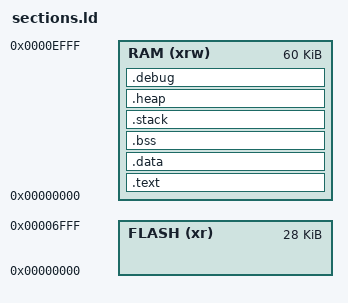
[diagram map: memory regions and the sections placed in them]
_STACK_SIZE = 2K;
_HEAP_SIZE = 2K;

MEMORY
{
    /* FLASH and RAM must have the same memory origin */
    FLASH(xr)       : ORIGIN = 0x00000000, LENGTH = 0x007000
    RAM  (xrw)       : ORIGIN = 0x00000000, LENGTH = 0x00F000
}

SECTIONS {
    /* The program code and other data goes into FLASH */
    .text :
    {
        . = ALIGN(4);
        *(.text)           /* .text sections (code) */
        *(.text*)          /* .text* sections (code) */
        *(.rodata)         /* .rodata sections (constants, strings, etc.) */
        *(.rodata*)        /* .rodata* sections (constants, strings, etc.) */
        *(.srodata)        /* .rodata sections (constants, strings, etc.) */
        *(.srodata*)       /* .rodata* sections (constants, strings, etc.) */
        . = ALIGN(4);
        _etext = .;        /* define a global symbol at end of code */
        _sidata = _etext;  /* This is used by the startup in order to initialize the .data secion */
        . = ALIGN(4);
    } >RAM


    /* This is the initialized data section
    The program executes knowing that the data is in the RAM
    but the loader puts the initial values in the FLASH (inidata).
    It is one task of the startup to copy the initial values from FLASH to RAM. */
    .data : AT ( _sidata )
    {
        . = ALIGN(4);
        _sdata = .;        /* create a global symbol at data start; used by startup code in order to initialise the .data section in RAM */
        . = ALIGN(4);
        /* We add small data before data, and align to 4, that seems to be the right way */
        *(.sdata)           /* .sdata sections */
        *(.sdata*)          /* .sdata* sections */
        . = ALIGN(4);
        *(.data)           /* .data sections */
        *(.data*)          /* .data* sections */
        . = ALIGN(4);
        _edata = .;        /* define a global symbol at data end; used by startup code in order to initialise the .data section in RAM */
    } >RAM

    /* Uninitialized data section */
    .bss :
    {
        . = ALIGN(4);
        _sbss = .;         /* define a global symbol at bss start; used by startup code */
        *(.bss)
        *(.bss*)
        *(.sbss)
        *(.sbss*)
        *(COMMON)

        . = ALIGN(4);
        _ebss = .;         /* define a global symbol at bss end; used by startup code */
    } >RAM

    /* Generate Stack and Heap definitions
    * Stack grows downwards
    */
   .stack : {
       _stack_end = .;
       . += _STACK_SIZE;
       . = ALIGN(4);
       _stack = .;
       __stack = _stack;
       . = ALIGN(4); 
    } > RAM

    /* Heap grows upwards */
    .heap : {
       . = ALIGN(4);
       _heap = .;
       _heap_start = .;
       . += _HEAP_SIZE;
       _heap_end = .;
    } > RAM   

    .debug : {
        /* Without this, the linker complains about the lack of .eh_frame*/
        KEEP (*(.eh_frame))
    } > RAM
}
